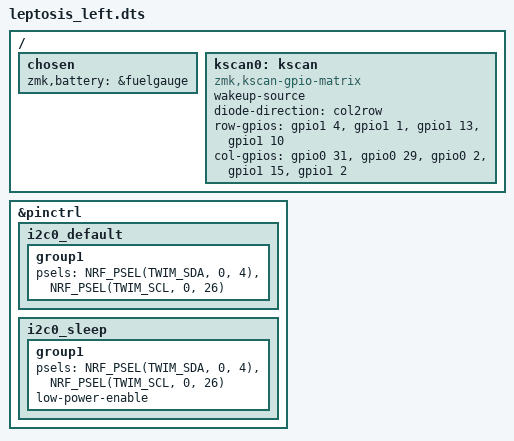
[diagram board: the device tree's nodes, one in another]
/*
*
* Copyright (c) 2025 Cheyao
* SPDX-License-Identifier: MIT
*
*/

#include "leptosis.dtsi"

/{
    chosen {
		zmk,battery = &fuelgauge;
    };

    kscan0: kscan {
        compatible = "zmk,kscan-gpio-matrix";
        wakeup-source;

        diode-direction = "col2row";
        row-gpios
            = <&gpio1  4 (GPIO_ACTIVE_HIGH | GPIO_PULL_DOWN)>
            , <&gpio1  1 (GPIO_ACTIVE_HIGH | GPIO_PULL_DOWN)>
            , <&gpio1 13 (GPIO_ACTIVE_HIGH | GPIO_PULL_DOWN)>
            , <&gpio1 10 (GPIO_ACTIVE_HIGH | GPIO_PULL_DOWN)>
            ;

        col-gpios
            = <&gpio0 31 GPIO_ACTIVE_HIGH>
            , <&gpio0 29 GPIO_ACTIVE_HIGH>
            , <&gpio0  2 GPIO_ACTIVE_HIGH>
            , <&gpio1 15 GPIO_ACTIVE_HIGH>
            , <&gpio1  2 GPIO_ACTIVE_HIGH>
            ;
    };
};

&pinctrl {
       i2c0_default: i2c0_default {
               group1 {
                       psels = <NRF_PSEL(TWIM_SDA, 0,  4)>,
                               <NRF_PSEL(TWIM_SCL, 0, 26)>;
               };
       };

       i2c0_sleep: i2c0_sleep {
               group1 {
                       psels = <NRF_PSEL(TWIM_SDA, 0,  4)>,
                               <NRF_PSEL(TWIM_SCL, 0, 26)>;
                       low-power-enable;
               };
       };
};
